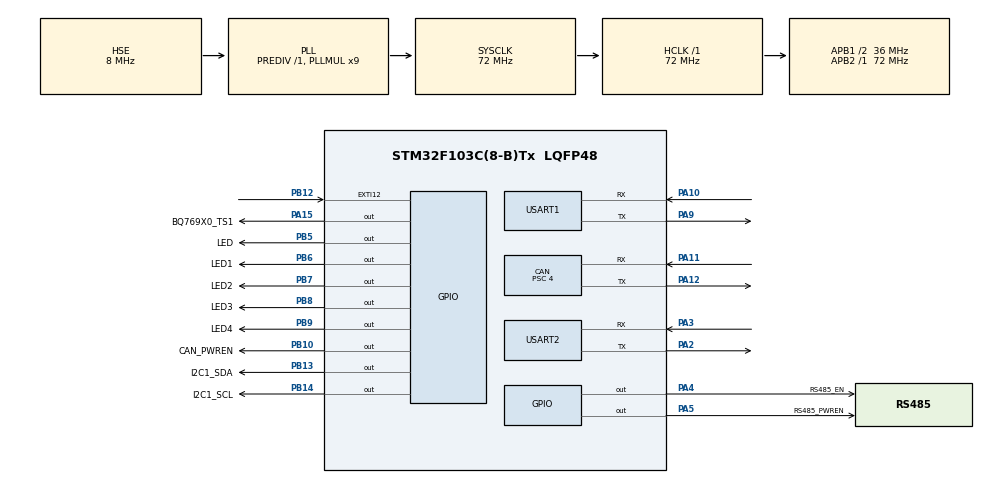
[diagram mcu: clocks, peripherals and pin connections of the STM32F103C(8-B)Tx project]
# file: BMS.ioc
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CAN.ABOM=ENABLE
CAN.AWUM=ENABLE
CAN.BS1=CAN_BS1_14TQ
CAN.BS2=CAN_BS2_3TQ
CAN.CalculateBaudRate=500000
CAN.CalculateTimeBit=2000
CAN.CalculateTimeQuantum=111.11111111111111
CAN.Prescaler=4
Mcu.Family=STM32F1
Mcu.Name=STM32F103C(8-B)Tx
Mcu.Package=LQFP48
NVIC.CAN1_RX1_IRQn=true\:2\:2\:true\:false\:true\:false\:true\:true\:true
NVIC.EXTI15_10_IRQn=true\:1\:1\:true\:false\:true\:false\:true\:true\:true
NVIC.PriorityGroup=NVIC_PRIORITYGROUP_2
NVIC.USART2_IRQn=true\:2\:1\:true\:false\:true\:false\:true\:true\:true
NVIC.USB_LP_CAN1_RX0_IRQn=true\:0\:0\:false\:false\:true\:false\:true\:true\:true
PA10.Mode=Asynchronous
PA10.Signal=USART1_RX
PA11.Mode=CAN_Activate
PA11.Signal=CAN_RX
PA12.Mode=CAN_Activate
PA12.Signal=CAN_TX
PA13.Mode=Serial_Wire
PA13.Signal=SYS_JTMS-SWDIO
PA14.Mode=Serial_Wire
PA14.Signal=SYS_JTCK-SWCLK
PA15.GPIO_Label=BQ769X0_TS1
PA15.Signal=GPIO_Output
PA2.Mode=Asynchronous
PA2.Signal=USART2_TX
PA3.Mode=Asynchronous
PA3.Signal=USART2_RX
PA4.GPIO_Label=RS485_EN
PA4.PinState=GPIO_PIN_SET
PA4.Signal=GPIO_Output
PA5.GPIO_Label=RS485_PWREN
PA5.GPIO_ModeDefaultOutputPP=GPIO_MODE_OUTPUT_PP
PA5.GPIO_PuPd=GPIO_NOPULL
PA5.PinState=GPIO_PIN_SET
PA5.Signal=GPIO_Output
PA9.Mode=Asynchronous
PA9.Signal=USART1_TX
PB10.GPIO_Label=CAN_PWREN
PB10.GPIO_ModeDefaultOutputPP=GPIO_MODE_OUTPUT_OD
PB10.GPIO_PuPd=GPIO_NOPULL
PB10.PinState=GPIO_PIN_SET
PB10.Signal=GPIO_Output
PB12.GPIO_PuPd=GPIO_NOPULL
PB12.Signal=GPXTI12
PB13.GPIO_Label=I2C1_SDA
PB13.GPIO_Speed=GPIO_SPEED_FREQ_HIGH
PB13.PinState=GPIO_PIN_SET
PB13.Signal=GPIO_Output
PB14.GPIO_Label=I2C1_SCL
PB14.Signal=GPIO_Output
PB5.GPIO_Label=LED
PB5.GPIO_Speed=GPIO_SPEED_FREQ_HIGH
PB5.PinState=GPIO_PIN_SET
PB5.Signal=GPIO_Output
PB6.GPIO_Label=LED1
PB6.GPIO_Speed=GPIO_SPEED_FREQ_HIGH
PB6.PinState=GPIO_PIN_SET
PB6.Signal=GPIO_Output
PB7.GPIO_Label=LED2
PB7.GPIO_Speed=GPIO_SPEED_FREQ_HIGH
PB7.PinState=GPIO_PIN_SET
PB7.Signal=GPIO_Output
PB8.GPIO_Label=LED3
PB8.GPIO_Speed=GPIO_SPEED_FREQ_HIGH
PB8.PinState=GPIO_PIN_SET
PB8.Signal=GPIO_Output
PB9.GPIO_Label=LED4
PB9.GPIO_Speed=GPIO_SPEED_FREQ_HIGH
PB9.PinState=GPIO_PIN_SET
PB9.Signal=GPIO_Output
PD0-OSC_IN.Mode=HSE-External-Oscillator
PD0-OSC_IN.Signal=RCC_OSC_IN
PD1-OSC_OUT.Mode=HSE-External-Oscillator
PD1-OSC_OUT.Signal=RCC_OSC_OUT
ProjectManager.HeapSize=0x400
ProjectManager.StackSize=0x400
ProjectManager.TargetToolchain=MDK-ARM V5
RCC.AHBFreq_Value=72000000
RCC.APB1CLKDivider=RCC_HCLK_DIV2
RCC.APB1Freq_Value=36000000
RCC.APB1TimFreq_Value=72000000
RCC.APB2Freq_Value=72000000
RCC.APB2TimFreq_Value=72000000
RCC.HCLKFreq_Value=72000000
RCC.PLLMUL=RCC_PLL_MUL9
RCC.PLLSourceVirtual=RCC_PLLSOURCE_HSE
RCC.SYSCLKFreq_VALUE=72000000
RCC.SYSCLKSource=RCC_SYSCLKSOURCE_PLLCLK
RCC.USBFreq_Value=72000000
RealThread.RT-Thread.3.1.5.RTOSJjdevice=true
RealThread.RT-Thread.3.1.5.RTOSJjkernel=true
RealThread.RT-Thread.3.1.5.RTOSJjshell=true
RealThread.RT-Thread.3.1.5.RT_CONSOLEBUF_SIZE=128
RealThread.RT-Thread.3.1.5.RT_DEBUG=1
RealThread.RT-Thread.3.1.5.RT_MAIN_THREAD_STACK_SIZE=1024
RealThread.RT-Thread.3.1.5.RT_TIMER_THREAD_STACK_SIZE=1024
RealThread.RT-Thread.3.1.5.RT_USING_EVENT=1
RealThread.RT-Thread.3.1.5.RT_USING_HEAP=1
RealThread.RT-Thread.3.1.5.RT_USING_MESSAGEQUEUE=1
RealThread.RT-Thread.3.1.5.RT_USING_MUTEX=0
USART1.VirtualMode=VM_ASYNC
USART2.VirtualMode=VM_ASYNC
VP_RealThread.RT-Thread_VS_RTOSJjdevice_3.1.5_3.1.5.Mode=RTOSJjdevice
VP_RealThread.RT-Thread_VS_RTOSJjkernel_3.1.5_3.1.5.Mode=RTOSJjkernel
VP_RealThread.RT-Thread_VS_RTOSJjshell_3.1.5_3.1.5.Mode=RTOSJjshell
board=custom

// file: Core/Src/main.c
/* USER CODE BEGIN Header */
/**
  ******************************************************************************
  * @file           : main.c
  * @brief          : Main program body
  ******************************************************************************
  * @attention
  *
  * Copyright (c) 2022 STMicroelectronics.
  * All rights reserved.
  *
  * This software is licensed under terms that can be found in the LICENSE file
  * in the root directory of this software component.
  * If no LICENSE file comes with this software, it is provided AS-IS.
  *
  ******************************************************************************
  */
/* USER CODE END Header */
#include "main.h"
#include "can.h"
#include "usart.h"
#include "gpio.h"

/* USER CODE BEGIN Includes */
#include <stdio.h>
#include <rtthread.h>

#include "board.h"

#include "bms_app.h"

#define DBG_TAG "main"
#define DBG_LVL DBG_LOG
#include "rtdbg.h"

/* USER CODE END Includes */

void SystemClock_Config(void);

int main(void)
{

  /* MCU Configuration--------------------------------------------------------*/

  /* Reset of all peripherals, Initializes the Flash interface and the Systick. */
  HAL_Init();

  /* Configure the system clock */
  SystemClock_Config();

  /* Initialize all configured peripherals */
  MX_GPIO_Init();
  MX_USART1_UART_Init();
  MX_USART2_UART_Init();
  MX_CAN_Init();
  /* USER CODE BEGIN 2 */

  //Board_Initialize();
  /*  主要的程序代码 -- 入口 */
  BMS_SysInitialize();

  /* USER CODE END 2 */

  /* Infinite loop */
  /* USER CODE BEGIN WHILE */
  while (1)
  {

 //CAN_SendTest();

	HAL_GPIO_TogglePin(LED_GPIO_Port, LED_Pin);
	//rt_kprintf("Hello RT-Thread!\r\n");
	rt_thread_mdelay(1000);  //th_read操作系统的延时函数

    /* USER CODE END WHILE */

  }
}

void SystemClock_Config(void)
{
  RCC_OscInitTypeDef RCC_OscInitStruct = {0};
  RCC_ClkInitTypeDef RCC_ClkInitStruct = {0};

  /** Initializes the RCC Oscillators according to the specified parameters
  * in the RCC_OscInitTypeDef structure.
  */
  RCC_OscInitStruct.OscillatorType = RCC_OSCILLATORTYPE_HSE;
  RCC_OscInitStruct.HSEState = RCC_HSE_ON;
  RCC_OscInitStruct.HSEPredivValue = RCC_HSE_PREDIV_DIV1;
  RCC_OscInitStruct.HSIState = RCC_HSI_ON;
  RCC_OscInitStruct.PLL.PLLState = RCC_PLL_ON;
  RCC_OscInitStruct.PLL.PLLSource = RCC_PLLSOURCE_HSE;
  RCC_OscInitStruct.PLL.PLLMUL = RCC_PLL_MUL9;
  if (HAL_RCC_OscConfig(&RCC_OscInitStruct) != HAL_OK)
  {
    Error_Handler();
  }

  /** Initializes the CPU, AHB and APB buses clocks
  */
  RCC_ClkInitStruct.ClockType = RCC_CLOCKTYPE_HCLK|RCC_CLOCKTYPE_SYSCLK
                              |RCC_CLOCKTYPE_PCLK1|RCC_CLOCKTYPE_PCLK2;
  RCC_ClkInitStruct.SYSCLKSource = RCC_SYSCLKSOURCE_PLLCLK;
  RCC_ClkInitStruct.AHBCLKDivider = RCC_SYSCLK_DIV1;
  RCC_ClkInitStruct.APB1CLKDivider = RCC_HCLK_DIV2;
  RCC_ClkInitStruct.APB2CLKDivider = RCC_HCLK_DIV1;

  if (HAL_RCC_ClockConfig(&RCC_ClkInitStruct, FLASH_LATENCY_2) != HAL_OK)
  {
    Error_Handler();
  }
}

void Error_Handler(void)
{
  __disable_irq();
  while (1)
  {
  }
}
